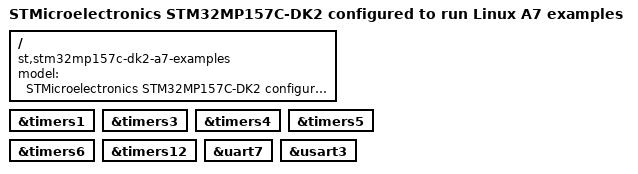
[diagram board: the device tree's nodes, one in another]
// SPDX-License-Identifier: (GPL-2.0-or-later OR BSD-3-Clause)
/*
 * Copyright (C) STMicroelectronics 2022 - All Rights Reserved
 * Author: Alexandre Torgue <alexandre.torgue@foss.st.com> for STMicroelectronics.
 */

/dts-v1/;

#include "stm32mp157c-dk2.dts"

/ {
	model = "STMicroelectronics STM32MP157C-DK2 configured to run Linux A7 examples";
	compatible = "st,stm32mp157c-dk2-a7-examples", "st,stm32mp157c-dk2", "st,stm32mp157";
};

&timers1 {
	status = "okay";
};

&timers3 {
	status = "okay";
};

&timers4 {
	status = "okay";
};

&timers5 {
	status = "okay";
};

&timers6 {
	status = "okay";
};

&timers12 {
	status = "okay";
};

&uart7 {
	status = "okay";
};

&usart3 {
	status = "okay";
};
